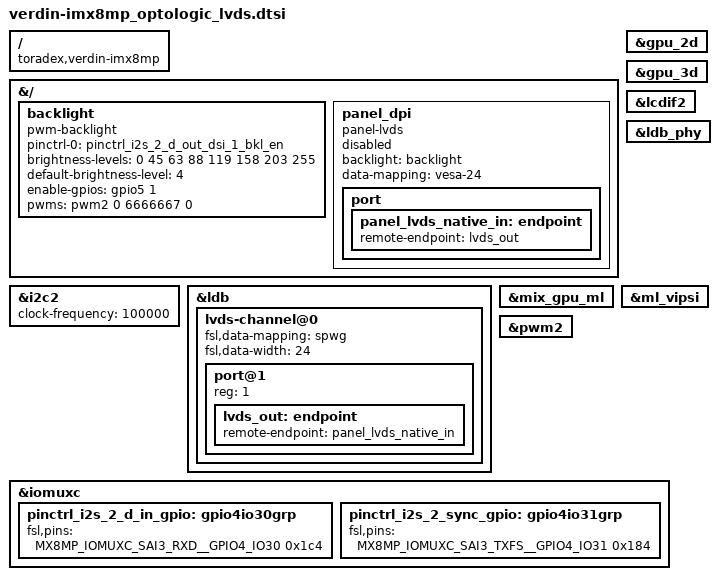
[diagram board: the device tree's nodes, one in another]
// SPDX-License-Identifier: GPL-2.0-or-later OR MIT
/*
 * Common LVDS/backlight/enablement for Verdin iMX8MP Optologic panels
 */

/ {
    compatible = "toradex,verdin-imx8mp";
};

&{/} {
    backlight: backlight {
        compatible = "pwm-backlight";
        pinctrl-names = "default";
        pinctrl-0 = <&pinctrl_i2s_2_d_out_dsi_1_bkl_en>;
        brightness-levels = <0 45 63 88 119 158 203 255>;
        default-brightness-level = <4>;
        /* Verdin I2S_2_D_OUT as GPIO (SODIMM 46) */
        enable-gpios = <&gpio5 1 GPIO_ACTIVE_HIGH>;
        /* Verdin PWM_2 (SODIMM 16) */
        pwms = <&pwm2 0 6666667 0>;
        status = "okay";
    };

    panel_dpi: panel_dpi { /* name to keep the compatibility with colibri panel */
        compatible = "panel-lvds";
        backlight = <&backlight>;
        data-mapping = "vesa-24";
        status = "disable";
        port {
            panel_lvds_native_in: endpoint {
                remote-endpoint = <&lvds_out>;
            };
        };
    };
};

&gpu_2d {
    status = "okay";
};

&gpu_3d {
    status = "okay";
};

/* Verdin I2C_2_DSI common bus settings; touch node is panel-specific */
&i2c2 {
    #address-cells = <1>;
    #size-cells = <0>;
    status = "okay";
    clock-frequency = <100000>;
};

&lcdif2 {
    status = "okay";
};

&ldb {
    status = "okay";

    lvds-channel@0 {
        fsl,data-mapping = "spwg";
        fsl,data-width = <24>;
        status = "okay";

        port@1 {
            reg = <1>;

            lvds_out: endpoint {
                remote-endpoint = <&panel_lvds_native_in>;
            };
        };
    };
};

&ldb_phy {
    status = "okay";
};

&mix_gpu_ml {
    status = "okay";
};

&ml_vipsi {
    status = "okay";
};

/* Verdin PWM_2 */
&pwm2 {
    status = "okay";
};

/* Touch INT/RESET pinmux (shared) */
&iomuxc {
    pinctrl_i2s_2_d_in_gpio: gpio4io30grp {
        fsl,pins =
            <MX8MP_IOMUXC_SAI3_RXD__GPIO4_IO30 0x1c4>; /* SODIMM 48 */
    };

    pinctrl_i2s_2_sync_gpio: gpio4io31grp {
        fsl,pins =
            <MX8MP_IOMUXC_SAI3_TXFS__GPIO4_IO31 0x184>; /* SODIMM 44 */
    };
};
